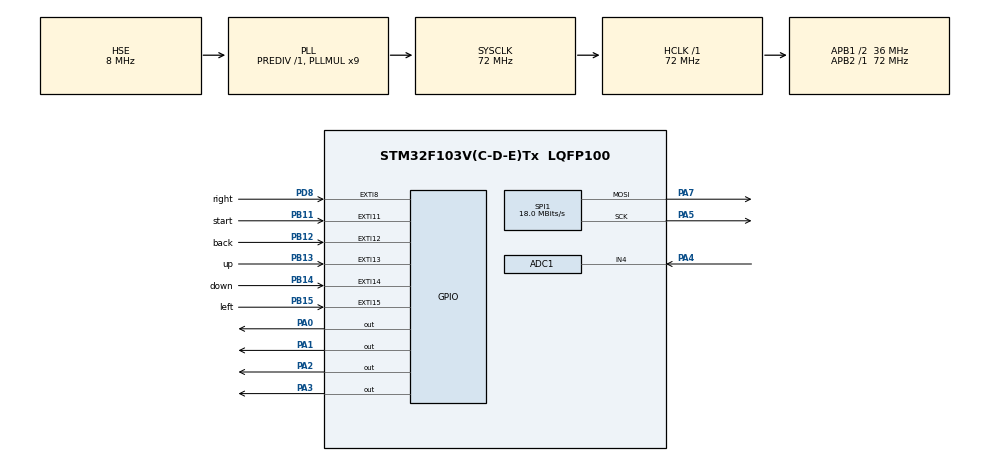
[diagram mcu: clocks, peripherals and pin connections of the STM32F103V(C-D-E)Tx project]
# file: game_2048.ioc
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ADC1.Channel-0\#ChannelRegularConversion=ADC_CHANNEL_4
ADC1.NbrOfConversionFlag=1
ADC1.Rank-0\#ChannelRegularConversion=1
ADC1.SamplingTime-0\#ChannelRegularConversion=ADC_SAMPLETIME_1CYCLE_5
ADC1.master=1
Dma.Request0=SPI1_TX
Dma.SPI1_TX.0.Direction=DMA_MEMORY_TO_PERIPH
Dma.SPI1_TX.0.Instance=DMA1_Channel3
Dma.SPI1_TX.0.MemDataAlignment=DMA_MDATAALIGN_BYTE
Dma.SPI1_TX.0.MemInc=DMA_MINC_ENABLE
Dma.SPI1_TX.0.Mode=DMA_NORMAL
Dma.SPI1_TX.0.PeriphDataAlignment=DMA_PDATAALIGN_BYTE
Dma.SPI1_TX.0.PeriphInc=DMA_PINC_DISABLE
Dma.SPI1_TX.0.Priority=DMA_PRIORITY_LOW
IWDG.Prescaler=IWDG_PRESCALER_64
IWDG.Reload=1250
Mcu.Family=STM32F1
Mcu.Name=STM32F103V(C-D-E)Tx
Mcu.Package=LQFP100
NVIC.DMA1_Channel3_IRQn=true\:0\:0\:false\:false\:true\:false\:true\:true
NVIC.EXTI15_10_IRQn=true\:0\:0\:false\:false\:true\:true\:true\:true
NVIC.EXTI9_5_IRQn=true\:0\:0\:false\:false\:true\:true\:true\:true
NVIC.PVD_IRQn=true\:0\:0\:false\:false\:true\:true\:true\:true
NVIC.PriorityGroup=NVIC_PRIORITYGROUP_4
NVIC.SPI1_IRQn=true\:0\:0\:false\:false\:true\:true\:true\:true
OSC_IN.Mode=HSE-External-Oscillator
OSC_IN.Signal=RCC_OSC_IN
OSC_OUT.Mode=HSE-External-Oscillator
OSC_OUT.Signal=RCC_OSC_OUT
PA0-WKUP.GPIO_Speed=GPIO_SPEED_FREQ_HIGH
PA0-WKUP.PinState=GPIO_PIN_RESET
PA0-WKUP.Signal=GPIO_Output
PA1.GPIO_Speed=GPIO_SPEED_FREQ_HIGH
PA1.Signal=GPIO_Output
PA13.Mode=Serial_Wire
PA13.Signal=SYS_JTMS-SWDIO
PA14.Mode=Serial_Wire
PA14.Signal=SYS_JTCK-SWCLK
PA2.GPIO_Speed=GPIO_SPEED_FREQ_HIGH
PA2.Signal=GPIO_Output
PA3.GPIO_Speed=GPIO_SPEED_FREQ_HIGH
PA3.PinState=GPIO_PIN_SET
PA3.Signal=GPIO_Output
PA4.Signal=ADCx_IN4
PA5.Mode=TX_Only_Simplex_Unidirect_Master
PA5.Signal=SPI1_SCK
PA7.Mode=TX_Only_Simplex_Unidirect_Master
PA7.Signal=SPI1_MOSI
PB11.GPIO_Label=start
PB11.GPIO_ModeDefaultEXTI=GPIO_MODE_IT_FALLING
PB11.GPIO_PuPd=GPIO_PULLUP
PB11.Signal=GPXTI11
PB12.GPIO_Label=back
PB12.GPIO_ModeDefaultEXTI=GPIO_MODE_IT_FALLING
PB12.GPIO_PuPd=GPIO_PULLUP
PB12.Signal=GPXTI12
PB13.GPIO_Label=up
PB13.GPIO_ModeDefaultEXTI=GPIO_MODE_IT_FALLING
PB13.GPIO_PuPd=GPIO_PULLUP
PB13.Signal=GPXTI13
PB14.GPIO_Label=down
PB14.GPIO_ModeDefaultEXTI=GPIO_MODE_IT_FALLING
PB14.GPIO_PuPd=GPIO_PULLUP
PB14.Signal=GPXTI14
PB15.GPIO_Label=left
PB15.GPIO_ModeDefaultEXTI=GPIO_MODE_IT_FALLING
PB15.GPIO_PuPd=GPIO_PULLUP
PB15.Signal=GPXTI15
PD8.GPIO_Label=right
PD8.GPIO_ModeDefaultEXTI=GPIO_MODE_IT_FALLING
PD8.GPIO_PuPd=GPIO_PULLUP
PD8.Signal=GPXTI8
ProjectManager.HeapSize=0x200
ProjectManager.StackSize=0x400
ProjectManager.TargetToolchain=CMake
RCC.ADCPresc=RCC_ADCPCLK2_DIV6
RCC.AHBFreq_Value=72000000
RCC.APB1CLKDivider=RCC_HCLK_DIV2
RCC.APB1Freq_Value=36000000
RCC.APB1TimFreq_Value=72000000
RCC.APB2Freq_Value=72000000
RCC.APB2TimFreq_Value=72000000
RCC.HCLKFreq_Value=72000000
RCC.PLLMUL=RCC_PLL_MUL9
RCC.PLLSourceVirtual=RCC_PLLSOURCE_HSE
RCC.SYSCLKFreq_VALUE=72000000
RCC.SYSCLKSource=RCC_SYSCLKSOURCE_PLLCLK
RCC.USBFreq_Value=72000000
SH.ADCx_IN4.0=ADC1_IN4,IN4
SPI1.BaudRatePrescaler=SPI_BAUDRATEPRESCALER_4
SPI1.CalculateBaudRate=18.0 MBits/s
SPI1.Direction=SPI_DIRECTION_2LINES
SPI1.Mode=SPI_MODE_MASTER
SPI1.VirtualType=VM_MASTER
VP_IWDG_VS_IWDG.Mode=IWDG_Activate
board=custom

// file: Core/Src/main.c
/* USER CODE BEGIN Header */
/**
  ******************************************************************************
  * @file           : main.c
  * @brief          : Main program body
  ******************************************************************************
  * @attention
  *
  * Copyright (c) 2026 STMicroelectronics.
  * All rights reserved.
  *
  * This software is licensed under terms that can be found in the LICENSE file
  * in the root directory of this software component.
  * If no LICENSE file comes with this software, it is provided AS-IS.
  *
  ******************************************************************************
  */
/* USER CODE END Header */
#include "main.h"
#include "adc.h"
#include "dma.h"
#include "iwdg.h"
#include "spi.h"
#include "gpio.h"

/* USER CODE BEGIN Includes */
#include "lvgl_port.h"
#include "st7735s.h"
#include "game.h"
/* USER CODE END Includes */

void SystemClock_Config(void);

/* USER CODE BEGIN 0 */
// static uint8_t key_last_state = 1; //按键默认高电平
/* USER CODE END 0 */

int main(void)
{

  /* MCU Configuration--------------------------------------------------------*/

  /* Reset of all peripherals, Initializes the Flash interface and the Systick. */
  HAL_Init();

  /* Configure the system clock */
  SystemClock_Config();

  /* Initialize all configured peripherals */
  MX_GPIO_Init();
  MX_DMA_Init();
  MX_SPI1_Init();
  MX_ADC1_Init();
  MX_IWDG_Init();
  /* USER CODE BEGIN 2 */
  st7735_init();   //初始化屏幕
  lv_init();
  lv_port_disp_init();
  layoutInit();
  switchLayout(&main_layout,0);
  /* USER CODE END 2 */

  /* Infinite loop */
  while (1)
  {

    /* USER CODE BEGIN 3 */
    keyEventListening();
    lv_timer_handler();
    HAL_IWDG_Refresh(&hiwdg);
  }
  /* USER CODE END 3 */
}

void SystemClock_Config(void)
{
  RCC_OscInitTypeDef RCC_OscInitStruct = {0};
  RCC_ClkInitTypeDef RCC_ClkInitStruct = {0};
  RCC_PeriphCLKInitTypeDef PeriphClkInit = {0};

  /** Initializes the RCC Oscillators according to the specified parameters
  * in the RCC_OscInitTypeDef structure.
  */
  RCC_OscInitStruct.OscillatorType = RCC_OSCILLATORTYPE_LSI|RCC_OSCILLATORTYPE_HSE;
  RCC_OscInitStruct.HSEState = RCC_HSE_ON;
  RCC_OscInitStruct.HSEPredivValue = RCC_HSE_PREDIV_DIV1;
  RCC_OscInitStruct.HSIState = RCC_HSI_ON;
  RCC_OscInitStruct.LSIState = RCC_LSI_ON;
  RCC_OscInitStruct.PLL.PLLState = RCC_PLL_ON;
  RCC_OscInitStruct.PLL.PLLSource = RCC_PLLSOURCE_HSE;
  RCC_OscInitStruct.PLL.PLLMUL = RCC_PLL_MUL9;
  if (HAL_RCC_OscConfig(&RCC_OscInitStruct) != HAL_OK)
  {
    Error_Handler();
  }

  /** Initializes the CPU, AHB and APB buses clocks
  */
  RCC_ClkInitStruct.ClockType = RCC_CLOCKTYPE_HCLK|RCC_CLOCKTYPE_SYSCLK
                              |RCC_CLOCKTYPE_PCLK1|RCC_CLOCKTYPE_PCLK2;
  RCC_ClkInitStruct.SYSCLKSource = RCC_SYSCLKSOURCE_PLLCLK;
  RCC_ClkInitStruct.AHBCLKDivider = RCC_SYSCLK_DIV1;
  RCC_ClkInitStruct.APB1CLKDivider = RCC_HCLK_DIV2;
  RCC_ClkInitStruct.APB2CLKDivider = RCC_HCLK_DIV1;

  if (HAL_RCC_ClockConfig(&RCC_ClkInitStruct, FLASH_LATENCY_2) != HAL_OK)
  {
    Error_Handler();
  }
  PeriphClkInit.PeriphClockSelection = RCC_PERIPHCLK_ADC;
  PeriphClkInit.AdcClockSelection = RCC_ADCPCLK2_DIV6;
  if (HAL_RCCEx_PeriphCLKConfig(&PeriphClkInit) != HAL_OK)
  {
    Error_Handler();
  }
}

void Error_Handler(void)
{
  __disable_irq();
  while (1)
  {
  }
}
